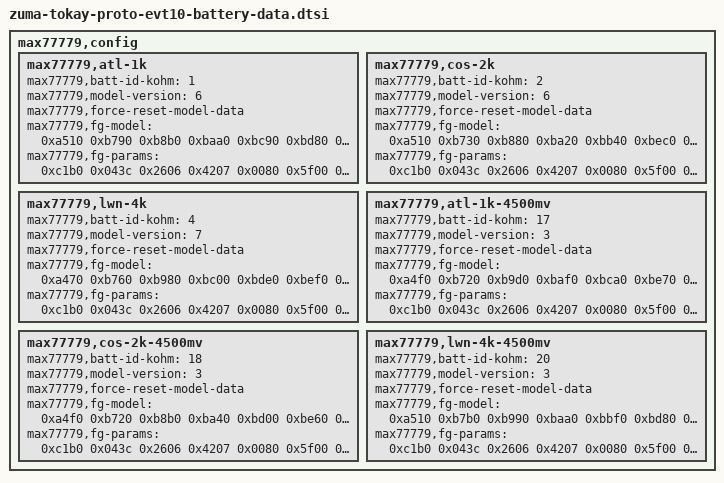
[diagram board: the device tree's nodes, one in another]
// SPDX-License-Identifier: GPL-2.0-only
/*
 * Battery device tree entries
 *
 * Copyright 2023 Google LLC
 *
 */

max77779,config {

	/* BC79_2mOhm_3347(4.48v)_ATL_RC2_ver2.ini, b/299336669#comment2 */
	max77779,atl-1k {
		max77779,batt-id-kohm = <1>;
		max77779,model-version = <6>;
		max77779,force-reset-model-data;
		max77779,fg-model = /bits/ 16 <
                        0xa510 0xb790 0xb8b0 0xbaa0 0xbc90 0xbd80 0xbe70 0xbf80
                        0xc1f0 0xc710 0xc9c0 0xce70 0xd220 0xd570 0xd8c0 0xdde0
                        0x0150 0x1390 0x0d00 0x1120 0x15c0 0x1600 0x1400 0x0f40
                        0x0780 0x08f0 0x06f0 0x06d0 0x05f0 0x07f0 0x0580 0x0580
		>;
		max77779,fg-params = /bits/ 16 <
			/* 0x00C0 */	0xc1b0	/* nNVCfg0 */
			/* 0x00B6 */	0x043c	/* RelaxCFG */
			/* 0x009F */	0x2606	/* nLearnCFG */
			/* 0x000C */	0x4207	/* Config */
			/* 0x00AB */	0x0080	/* Config2 */
			/* 0x00BC */	0x5f00	/* nFullSOCthr */
			/* 0x00A9 */	0x0700	/* nFullCAPRep */
			/* 0x00B3 */	0x0700	/* nDesignCap */
			/* 0x0046 */	0x0C80	/* dPacc */
			/* 0x00A5 */	0x0700	/* nFullCAPNom */
			/* 0x00C6 */	0xa55a	/* nV_empty */
			/* 0x00A0 */	0x3c00	/* nQRTable00 */
			/* 0x00A1 */	0x1c80	/* nQRTable10 */
			/* 0x00A2 */	0x0d00	/* nQRTable20 */
			/* 0x00A3 */	0x0a00	/* nQRTable30 */
			/* 0x00A6 */	0x05c0	/* nRCOMP0 */
			/* 0x00A7 */	0x1a02	/* nTempCo */
			/* 0x009C */	0x023e	/* nIChgTerm */
			/* 0x00B2 */	0x3850	/* nMiscCFG */
			/* 0x009E */	0x0400	/* nModelCfg */
			/* 0x00CA */	0xC8FF	/* nThermCfg */
			/* 0x009D */	0xCEA4	/* nFilterCfg */
		>;
	};

	/* BC79_2mOhm_3348(4.48v)_COS_RC2_ver2.ini, b/299336669#comment2 */
	max77779,cos-2k {
		max77779,batt-id-kohm = <2>;
		max77779,model-version = <6>;
		max77779,force-reset-model-data;
		max77779,fg-model = /bits/ 16 <
                        0xa510 0xb730 0xb880 0xba20 0xbb40 0xbec0 0xc020 0xc1c0
                        0xc460 0xc7b0 0xcc10 0xd160 0xd4f0 0xd860 0xdb00 0xde90
                        0x0130 0x1110 0x0e00 0x0cd0 0x1010 0x1300 0x0d80 0x0b80
                        0x0730 0x06c0 0x06f0 0x06a0 0x06f0 0x07e0 0x0700 0x0700
		>;
		max77779,fg-params = /bits/ 16 <
			/* 0x00C0 */	0xc1b0	/* nNVCfg0 */
			/* 0x00B6 */	0x043c	/* RelaxCFG */
			/* 0x009F */	0x2606	/* nLearnCFG */
			/* 0x000C */	0x4207	/* Config */
			/* 0x00AB */	0x0080	/* Config2 */
			/* 0x00BC */	0x5f00	/* nFullSOCthr */
			/* 0x00A9 */	0x0700	/* nFullCAPRep */
			/* 0x00B3 */	0x0700	/* nDesignCap */
			/* 0x0046 */	0x0C80	/* dPacc */
			/* 0x00A5 */	0x0700	/* nFullCAPNom */
			/* 0x00C6 */	0xa55a	/* nV_empty */
			/* 0x00A0 */	0x2900	/* nQRTable00 */
			/* 0x00A1 */	0x1480	/* nQRTable10 */
			/* 0x00A2 */	0x0a00	/* nQRTable20 */
			/* 0x00A3 */	0x0780	/* nQRTable30 */
			/* 0x00A6 */	0x04e0	/* nRCOMP0 */
			/* 0x00A7 */	0x1e02	/* nTempCo */
			/* 0x009C */	0x023e	/* nIChgTerm */
			/* 0x00B2 */	0x3850	/* nMiscCFG */
			/* 0x009E */	0x0400	/* nModelCfg */
			/* 0x00CA */	0xC8FF	/* nThermCfg */
			/* 0x009D */	0xCEA4	/* nFilterCfg */
		>;
	};

	/* BC79_2mOhm_3348(4.48v)_LWN_RC2_ver2.ini, b/299336669#comment2 */
	max77779,lwn-4k {
		max77779,batt-id-kohm = <4>;
		max77779,model-version = <7>;
		max77779,force-reset-model-data;
		max77779,fg-model = /bits/ 16 <
                        0xa470 0xb760 0xb980 0xbc00 0xbde0 0xbef0 0xc060 0xc220
                        0xc450 0xc7a0 0xca50 0xcd10 0xd0b0 0xd450 0xd830 0xde70
                        0x0170 0x0f30 0x0d10 0x1500 0x0f40 0x1200 0x0d40 0x0af0
                        0x05f0 0x06d0 0x07b0 0x06f0 0x05f0 0x07b0 0x06c0 0x06c0
		>;
		max77779,fg-params = /bits/ 16 <
			/* 0x00C0 */	0xc1b0	/* nNVCfg0 */
			/* 0x00B6 */	0x043c	/* RelaxCFG */
			/* 0x009F */	0x2606	/* nLearnCFG */
			/* 0x000C */	0x4207	/* Config */
			/* 0x00AB */	0x0080	/* Config2 */
			/* 0x00BC */	0x5f00	/* nFullSOCthr */
			/* 0x00A9 */	0x0700	/* nFullCAPRep */
			/* 0x00B3 */	0x0700	/* nDesignCap */
			/* 0x0046 */	0x0C80	/* dPacc */
			/* 0x00A5 */	0x0700	/* nFullCAPNom */
			/* 0x00C6 */	0xa55a	/* nV_empty */
			/* 0x00A0 */	0x3b00	/* nQRTable00 */
			/* 0x00A1 */	0x1b00	/* nQRTable10 */
			/* 0x00A2 */	0x0b00	/* nQRTable20 */
			/* 0x00A3 */	0x0900	/* nQRTable30 */
			/* 0x00A6 */	0x05b0	/* nRCOMP0 */
			/* 0x00A7 */	0x1a02	/* nTempCo */
			/* 0x009C */	0x023e	/* nIChgTerm */
			/* 0x00B2 */	0x3850	/* nMiscCFG */
			/* 0x009E */	0x0400	/* nModelCfg */
			/* 0x00CA */	0xC8FF	/* nThermCfg */
			/* 0x009D */	0xCEA4	/* nFilterCfg */
		>;
	};

	/* BC79_2mOhm_3524(4.5V)_ATL_RC2_Ver1.txt, b/299336669#comment6 */
	max77779,atl-1k-4500mv {
		max77779,batt-id-kohm = <17>;
		max77779,model-version = <3>;
		max77779,force-reset-model-data;
		max77779,fg-model = /bits/ 16 <
                        0xa4f0 0xb720 0xb9d0 0xbaf0 0xbca0 0xbe70 0xbfa0 0xc260
                        0xc3c0 0xc640 0xca10 0xcdc0 0xd080 0xd3b0 0xd760 0xded0
                        0x0100 0x0f20 0x0750 0x1700 0x1000 0x1b10 0x0d40 0x06f0
                        0x08f0 0x06f0 0x0770 0x06f0 0x07c0 0x05e0 0x05f0 0x05f0
		>;
		max77779,fg-params = /bits/ 16 <
			/* 0x00C0 */	0xc1b0	/* nNVCfg0 */
			/* 0x00B6 */	0x043c	/* RelaxCFG */
			/* 0x009F */	0x2606	/* nLearnCFG */
			/* 0x000C */	0x4207	/* Config */
			/* 0x00AB */	0x0080	/* Config2 */
			/* 0x00BC */	0x5f00	/* nFullSOCthr */
			/* 0x00A9 */	0x0780	/* nFullCAPRep */
			/* 0x00B3 */	0x0780	/* nDesignCap */
			/* 0x0046 */	0x0C80	/* dPacc */
			/* 0x00A5 */	0x0780	/* nFullCAPNom */
			/* 0x00C6 */	0xa55a	/* nV_empty */
			/* 0x00A0 */	0x3e0a	/* nQRTable00 */
			/* 0x00A1 */	0x1c00	/* nQRTable10 */
			/* 0x00A2 */	0x0b00	/* nQRTable20 */
			/* 0x00A3 */	0x0800	/* nQRTable30 */
			/* 0x00A6 */	0x05f0	/* nRCOMP0 */
			/* 0x00A7 */	0x1a02	/* nTempCo */
			/* 0x009C */	0x0247	/* nIChgTerm */
			/* 0x00B2 */	0x3850	/* nMiscCFG */
			/* 0x009E */	0x0400	/* nModelCfg */
			/* 0x00CA */	0xC8FF	/* nThermCfg */
			/* 0x009D */	0xCEA4	/* nFilterCfg */
		>;
	};

	/* BC79_2mOhm_3525(4.5V)_COS_RC2_Ver1.txt, b/299336669#comment6 */
	max77779,cos-2k-4500mv {
		max77779,batt-id-kohm = <18>;
		max77779,model-version = <3>;
		max77779,force-reset-model-data;
		max77779,fg-model = /bits/ 16 <
                        0xa4f0 0xb720 0xb8b0 0xba40 0xbd00 0xbe60 0xbfa0 0xc120
                        0xc2e0 0xc650 0xc9c0 0xcd50 0xd100 0xd800 0xdb00 0xdf20
                        0x0130 0x0f00 0x0d00 0x1000 0x1460 0x1300 0x0e40 0x0e90
                        0x06e0 0x06f0 0x07b0 0x05f0 0x06c0 0x07f0 0x05c0 0x05c0
		>;
		max77779,fg-params = /bits/ 16 <
			/* 0x00C0 */	0xc1b0	/* nNVCfg0 */
			/* 0x00B6 */	0x043c	/* RelaxCFG */
			/* 0x009F */	0x2606	/* nLearnCFG */
			/* 0x000C */	0x4207	/* Config */
			/* 0x00AB */	0x0080	/* Config2 */
			/* 0x00BC */	0x5f00	/* nFullSOCthr */
			/* 0x00A9 */	0x0780	/* nFullCAPRep */
			/* 0x00B3 */	0x0780	/* nDesignCap */
			/* 0x0046 */	0x0C80	/* dPacc */
			/* 0x00A5 */	0x0780	/* nFullCAPNom */
			/* 0x00C6 */	0xa55a	/* nV_empty */
			/* 0x00A0 */	0x360d	/* nQRTable00 */
			/* 0x00A1 */	0x1b84	/* nQRTable10 */
			/* 0x00A2 */	0x0e00	/* nQRTable20 */
			/* 0x00A3 */	0x0b00	/* nQRTable30 */
			/* 0x00A6 */	0x05f0	/* nRCOMP0 */
			/* 0x00A7 */	0x1e02	/* nTempCo */
			/* 0x009C */	0x0247	/* nIChgTerm */
			/* 0x00B2 */	0x3850	/* nMiscCFG */
			/* 0x009E */	0x0400	/* nModelCfg */
			/* 0x00CA */	0xC8FF	/* nThermCfg */
			/* 0x009D */	0xCEA4	/* nFilterCfg */
		>;
	};

	/* BC79_2mOhm_3526(4.5V)_LWN_RC2_Ver1.txt, b/299336669#comment6 */
	max77779,lwn-4k-4500mv {
		max77779,batt-id-kohm = <20>;
		max77779,model-version = <3>;
		max77779,force-reset-model-data;
		max77779,fg-model = /bits/ 16 <
                        0xa510 0xb7b0 0xb990 0xbaa0 0xbbf0 0xbd80 0xbe80 0xbfb0
                        0xc2a0 0xc620 0xc9b0 0xcd50 0xd110 0xd7a0 0xdb50 0xdf40
                        0x0130 0x1310 0x0a00 0x1200 0x0f00 0x1710 0x1440 0x0dd0
                        0x07e0 0x06d0 0x06f0 0x06d0 0x06f0 0x07f0 0x04a0 0x04a0
		>;
		max77779,fg-params = /bits/ 16 <
			/* 0x00C0 */	0xc1b0	/* nNVCfg0 */
			/* 0x00B6 */	0x043c	/* RelaxCFG */
			/* 0x009F */	0x2606	/* nLearnCFG */
			/* 0x000C */	0x4207	/* Config */
			/* 0x00AB */	0x0080	/* Config2 */
			/* 0x00BC */	0x5f00	/* nFullSOCthr */
			/* 0x00A9 */	0x0780	/* nFullCAPRep */
			/* 0x00B3 */	0x0780	/* nDesignCap */
			/* 0x0046 */	0x0C80	/* dPacc */
			/* 0x00A5 */	0x0780	/* nFullCAPNom */
			/* 0x00C6 */	0xa55a	/* nV_empty */
			/* 0x00A0 */	0x4285	/* nQRTable00 */
			/* 0x00A1 */	0x2082	/* nQRTable10 */
			/* 0x00A2 */	0x0f00	/* nQRTable20 */
			/* 0x00A3 */	0x0b00	/* nQRTable30 */
			/* 0x00A6 */	0x05d0	/* nRCOMP0 */
			/* 0x00A7 */	0x1902	/* nTempCo */
			/* 0x009C */	0x0247	/* nIChgTerm */
			/* 0x00B2 */	0x3850	/* nMiscCFG */
			/* 0x009E */	0x0400	/* nModelCfg */
			/* 0x00CA */	0xC8FF	/* nThermCfg */
			/* 0x009D */	0xCEA4	/* nFilterCfg */
		>;
	};
};
